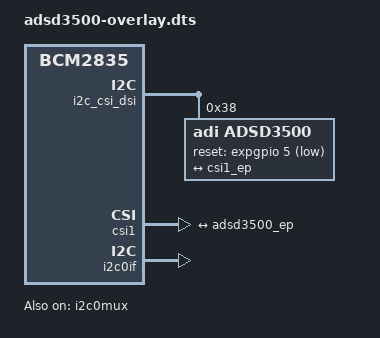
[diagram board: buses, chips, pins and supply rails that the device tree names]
// SPDX-License-Identifier: GPL-2.0-only
/*
*  Definitions for ADSD3500 TOF module on VC I2C bus
*/ 
/dts-v1/;
/plugin/;

#include <dt-bindings/gpio/gpio.h>

/{
	compatible = "brcm,bcm2835";

	fragment@0 {
		target = <&i2c_csi_dsi>;
		__overlay__ {
			#address-cells = <1>;
			#size-cells = <0>;
			status = "okay";

			adsd3500: adsd3500@38 {
				compatible = "adi,adsd3500";
				reg = <0x38>;
				status = "okay";
				reset-gpios = <&expgpio 5 GPIO_ACTIVE_LOW>;
				port {
					adsd3500_ep: endpoint {
						remote-endpoint = <&csi1_ep>;
						clock-lanes = <0>;
						data-lanes = <1 2>;
						link-frequencies =
							/bits/ 64 <732000000>;
					};
				};
			};
		};
	};

	fragment@1 {
		target = <&csi1>;
		__overlay__ {
			status = "okay";

			port {
				csi1_ep: endpoint {
					remote-endpoint = <&adsd3500_ep>;
					clock-lanes = <0>;
					data-lanes = <1 2>;
				};
			};
		};
	};

	fragment@2 {
		target = <&i2c0if>;
		__overlay__ {
			status = "okay";
		};
	};

	fragment@3 {
		target-path="/";
		__overlay__ {
			
		};
	};

	fragment@4 {
		target = <&i2c0mux>;
		__overlay__ {
			status = "okay";
		};
	};

	fragment@5 {
		__overlay__ {
			status = "okay";
		};
	};

	__overrides__ {
	};
};
